AUTOSAR XML (schema 4-0-3)
standard types defined: boolean, float32, float64, sint16, sint32, sint8, uint16, uint32, uint8
package /ApplDataTypes
  app type Rainfall: category=VALUE
  app type SwitchState: category=VALUE
  app type WipeRequest: category=VALUE
package /AutoWiperController
  composition sw component type AWCTopLevel
    5 x component:
      CddRainSensor: type=CddRainSensor
      CddWiperSwitch: type=CddWiperSwitch
      CddDisplayRain: type=CddDisplayRain
      CddWiperActuator: type=CddWiperActuator
      AutoWiperController: type=AutoWiperController
    connect CddRainSensor.RainfallOut -> AutoWiperController.RainfallInAWC
    connect CddRainSensor.RainfallOut -> CddDisplayRain.RainfallInDR
    connect CddWiperSwitch.WiperSwitchOut -> AutoWiperController.WiperSwitchIn
    connect AutoWiperController.WipeRequestOut -> CddWiperActuator.WipeRequestIn
  data type mapping set AWC_DTM
    data-type-maps:
      application-data-type=Rainfall, implementation-data-type=Rainfall
      application-data-type=SwitchState, implementation-data-type=SwitchState
      application-data-type=WipeRequest, implementation-data-type=WipeRequest
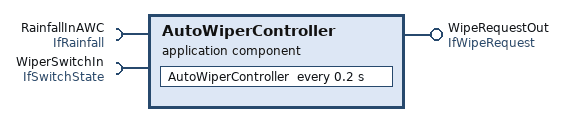
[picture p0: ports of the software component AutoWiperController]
  application sw component type AutoWiperController
    require port RainfallInAWC: required-interface=IfRainfall
    require port WiperSwitchIn: required-interface=IfSwitchState
    provide port WipeRequestOut: nonqueued-sender-com-spec{data-element=request, transmission-acknowledge=timeout=0, init-value=constant-reference={short-label=ReferenceToConstant, constant=IV_Request}}, provided-interface=IfWipeRequest
    behavior IB_AWC: data-type-mapping=AWC_DTM, handle-termination-and-restart=NO-SUPPORT
      timing event TimingEvent: start-on-event=AutoWiperController, period=0.2
      runnable AutoWiperController
        data-send-points:
          access VariableAccess: accessed-variable=WipeRequestOut.request
        sync call SynchronousServerCallPoint: operation=RainfallInAWC.GetRainfall, timeout=0
        sync call SynchronousServerCallPoint1: operation=WiperSwitchIn.GetWiperSwitchState, timeout=0
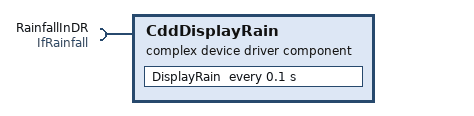
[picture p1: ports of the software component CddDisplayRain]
  complex device driver sw component type CddDisplayRain
    require port RainfallInDR: required-interface=IfRainfall
    behavior IB_DR: data-type-mapping=AWC_DTM, handle-termination-and-restart=NO-SUPPORT
      timing event TimingEvent: start-on-event=DisplayRain, period=0.1
      runnable DisplayRain
        sync call SynchronousServerCallPoint: operation=RainfallInDR.GetRainfall, timeout=0
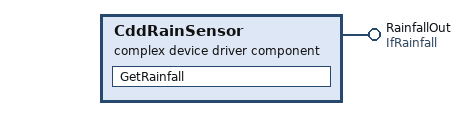
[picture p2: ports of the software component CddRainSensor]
  complex device driver sw component type CddRainSensor
    provide port RainfallOut: provided-interface=IfRainfall
    behavior IB_RS: data-type-mapping=AWC_DTM, handle-termination-and-restart=NO-SUPPORT
      operation invoked event OperationInvokedEvent: start-on-event=GetRainfall, operation=RainfallOut.GetRainfall
      runnable GetRainfall
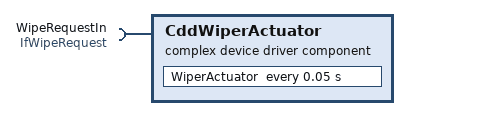
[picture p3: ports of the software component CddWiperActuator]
  complex device driver sw component type CddWiperActuator
    require port WipeRequestIn: required-interface=IfWipeRequest
    behavior IB_WA: data-type-mapping=AWC_DTM, handle-termination-and-restart=NO-SUPPORT
      timing event TimingEvent: start-on-event=WiperActuator, period=0.05
      runnable WiperActuator
        data-receive-point-by-arguments:
          access VariableAccess: accessed-variable=WipeRequestIn.request
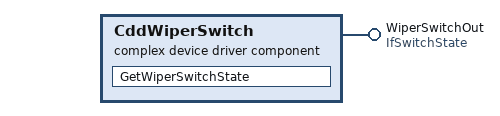
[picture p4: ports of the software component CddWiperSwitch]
  complex device driver sw component type CddWiperSwitch
    provide port WiperSwitchOut: provided-interface=IfSwitchState
    behavior IB_WS: data-type-mapping=AWC_DTM, handle-termination-and-restart=NO-SUPPORT
      operation invoked event OperationInvokedEvent: start-on-event=GetWiperSwitchState, operation=WiperSwitchOut.GetWiperSwitchState
      runnable GetWiperSwitchState
  constant specification IV_Request: value-spec=TextValue:FALSE
package /ImplDataTypes
  impl type Rainfall: category=VALUE, base-type=uint8
  impl type SwitchState: category=VALUE, base-type=uint8
  impl type WipeRequest: category=VALUE, base-type=boolean
package /Interfaces
  client server interface IfRainfall
    operation GetRainfall
      arg rain: type=Rainfall, direction=OUT
  client server interface IfSwitchState
    operation GetWiperSwitchState
      arg state: type=SwitchState, direction=OUT
  sender receiver interface IfWipeRequest
    data request: type=WipeRequest
package /System
  ecuc value collection EcucValueCollection: ecu-extract=SystemAWC, ecuc-values=[Os, Rte]
  system SystemAWC: system-version=1.0.0
    root-software-compositions:
      root sw composition prototype RootSwCompositionPrototype: software-composition=AWCTopLevel
